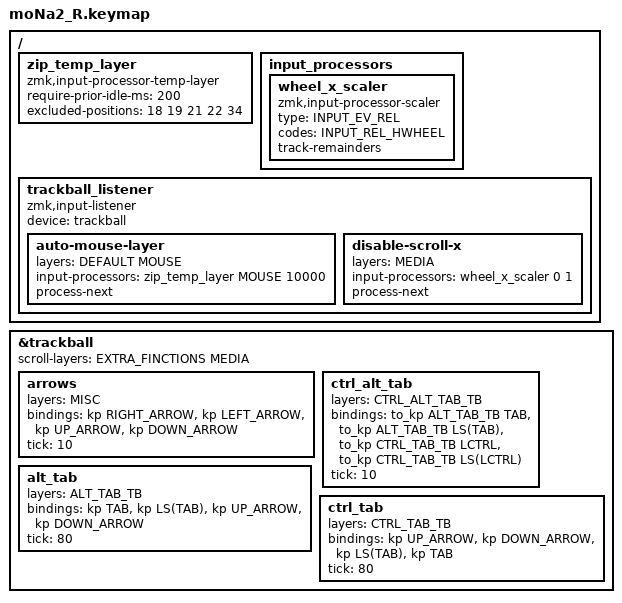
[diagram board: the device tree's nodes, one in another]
#include "moNa2_L.keymap"

#include <input/processors.dtsi>
#include <zephyr/dt-bindings/input/input-event-codes.h>
/ {
    /omit-if-no-ref/ zip_temp_layer: zip_temp_layer {
        compatible = "zmk,input-processor-temp-layer";
        #input-processor-cells = <2>;
        require-prior-idle-ms = <200>;
        excluded-positions = <
            18 // J
            19 // K
            // 20 // L
            21 // ;
            22 // Z
            // 31 // .
            // 32 // ,
            // 33 // /
            34 // Ctrl
        >;
    };

    input_processors {
        wheel_x_scaler: wheel_x_scaler {
            compatible = "zmk,input-processor-scaler";
            #input-processor-cells = <2>;
            type = <INPUT_EV_REL>;
            codes = <INPUT_REL_HWHEEL>;
            track-remainders;
        };
    };

    trackball_listener {
        compatible = "zmk,input-listener";
        device = <&trackball>;

        auto-mouse-layer {
            layers = <DEFAULT MOUSE>;
            input-processors = <&zip_temp_layer MOUSE 10000>;
            process-next;
        };

        disable-scroll-x {
            layers = <MEDIA>;
            input-processors = <&wheel_x_scaler 0 1>;
            process-next;
        };
    };
};

&trackball {
    scroll-layers = <EXTRA_FINCTIONS MEDIA>;
    // snipe-layers = <3>;

    arrows {
        layers = <MISC>;
        bindings =
            <&kp RIGHT_ARROW>,
            <&kp LEFT_ARROW>,
            <&kp UP_ARROW>,
            <&kp DOWN_ARROW>;

        tick = <10>;
    };

    // volume {
    //     layers = <MEDIA>;
    //     bindings =
    //         <&none>,
    //         <&none>,
    //         <&kp C_VOLUME_UP>,
    //         <&kp C_VOLUME_DOWN>;
    // };

    ctrl_alt_tab {
        layers = <CTRL_ALT_TAB_TB>;
        bindings =
            <&to_kp ALT_TAB_TB TAB>,
            <&to_kp ALT_TAB_TB LS(TAB)>,
            <&to_kp CTRL_TAB_TB LCTRL>,
            <&to_kp CTRL_TAB_TB LS(LCTRL)>;
        tick = <10>;
    };

    alt_tab {
        layers = <ALT_TAB_TB>;
        bindings =
            <&kp TAB>,
            <&kp LS(TAB)>,
            <&kp UP_ARROW>,
            <&kp DOWN_ARROW>;

        tick = <80>;
    };

    ctrl_tab {
        layers = <CTRL_TAB_TB>;
        bindings =
            <&kp UP_ARROW>,
            <&kp DOWN_ARROW>,
            <&kp LS(TAB)>,
            <&kp TAB>;

        tick = <80>;
    };
};
